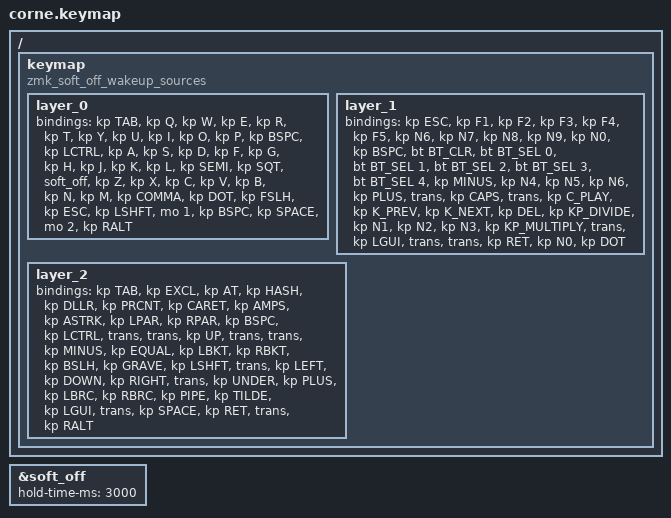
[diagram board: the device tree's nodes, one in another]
/*
 * Copyright (c) 2020 The ZMK Contributors
 *
 * SPDX-License-Identifier: MIT
 */

#include <behaviors.dtsi>
#include <dt-bindings/zmk/keys.h>
#include <dt-bindings/zmk/bt.h>

// layer mods
//#define  default 0
//#define  lower   1
//#define  upper   2

&soft_off {
    hold-time-ms = <3000>; // Only turn off it the key is held for 3 seconds or longer.
};



//&kscan0{
//        compatible = "zmk,soft-off-wakeup-sources";
//        wakeup-sources:
//    type: phandles
//    required: true
//    description: List of wakeup-sources that should be enabled to wake the system from forced soft-off state.
//}



/ {
        keymap {
                compatible = "zmk,keymap";
                compatible = "zmk_soft_off_wakeup_sources";
                 

                layer_0 {
// -----------------------------------------------------------------------------------------
// |  TAB |  Q  |  W  |  E  |  R  |  T  |   |  Y  |  U   |  I  |  O  |  P  | BSPC |
// | CTRL |  A  |  S  |  D  |  F  |  G  |   |  H  |  J   |  K  |  L  |  ;  |  '   |
// | off  |  Z  |  X  |  C  |  V  |  B  |   |  N  |  M   |  ,  |  .  |  /  | ESC  |
//                    | SHFT | LWR | BSPC |   | SPC | RSE  | ALT |
                        bindings = <
   &kp TAB   &kp Q &kp W &kp E &kp R &kp T   &kp Y &kp U  &kp I     &kp O   &kp P    &kp BSPC
   &kp LCTRL &kp A &kp S &kp D &kp F &kp G   &kp H &kp J  &kp K     &kp L   &kp SEMI &kp SQT
   &soft_off &kp Z &kp X &kp C &kp V &kp B   &kp N &kp M  &kp COMMA &kp DOT &kp FSLH &kp ESC
                  &kp LSHFT &mo 1 &kp BSPC   &kp SPACE &mo 2 &kp RALT
                        >;
                };
                layer_1 {
// -----------------------------------------------------------------------------------------
// |  EXC |  f1 |  f2 |  f3 |  f4 |  f5 |   |  6  |  7  |  8  |  9  |  0  | BSPC |
// | BTCLR| BT1 | BT2 | BT3 | BT4 | BT5 |   | -   | 4   |  5  | 6   |  +   |      |
// | CAPS |     |play |back | ffwd|  del|   |  div| 1   |  2  | 3   |  *   |      |
//                    | GUI |     |     |   | ENT |  0  |  >  |
                        bindings = <
   &kp ESC    &kp F1       &kp F2       &kp F3       &kp F4       &kp F5         &kp N6   &kp N7   &kp N8 &kp N9    &kp N0 &kp BSPC
   &bt BT_CLR &bt BT_SEL 0 &bt BT_SEL 1 &bt BT_SEL 2 &bt BT_SEL 3 &bt BT_SEL 4   &kp MINUS &kp N4 &kp N5 &kp N6 &kp PLUS &trans
   &kp CAPS  &trans       &kp C_PLAY  &kp K_PREV       &kp K_NEXT       &kp DEL        &kp KP_DIVIDE  &kp N1   &kp N2  &kp N3    &kp KP_MULTIPLY  &trans
                                    &kp LGUI     &trans       &trans      &kp RET  &kp N0   &kp DOT 
                        >;
                };

                layer_2 {
// -----------------------------------------------------------------------------------------
// |  TAB |  !  |  @  |  #  |  $  |  %  |   |  ^  |  &  |  *  |  (  |  )  | BSPC |
// | CTRL |     |     | UP  |     |     |   |  -  |  =  |  [  |  ]  |  \  |  `   |
// | SHFT |     | LFT | DWN | RGT |     |   |  _  |  +  |  {  |  }  | "|" |  ~   |
//                    | GUI |     | SPC |   | ENT |     | ALT |
                        bindings = <
   &kp  TAB  &kp EXCL &kp AT   &kp HASH   &kp DLLR   &kp PRCNT   &kp CARET &kp AMPS  &kp ASTRK &kp LPAR &kp RPAR &kp BSPC
   &kp LCTRL &trans   &trans   &kp UP     &trans     &trans      &kp MINUS &kp EQUAL &kp LBKT  &kp RBKT &kp BSLH &kp GRAVE
   &kp LSHFT &trans   &kp LEFT &kp DOWN   &kp RIGHT  &trans      &kp UNDER &kp PLUS  &kp LBRC  &kp RBRC &kp PIPE &kp TILDE
                             &kp LGUI &trans   &kp SPACE   &kp RET   &trans    &kp RALT
                        >;
                };
        };
};
